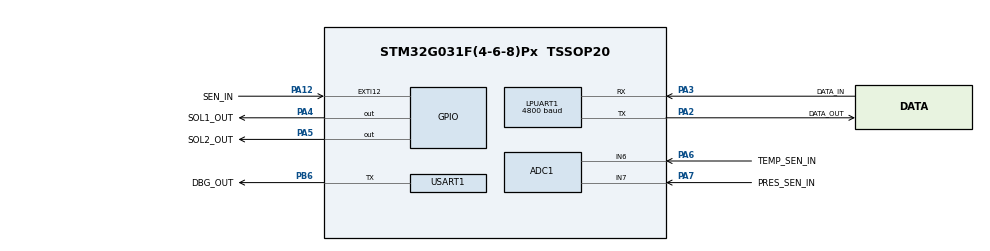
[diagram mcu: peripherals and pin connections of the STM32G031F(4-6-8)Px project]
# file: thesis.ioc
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ADC1.Channel-1\#ChannelRegularConversion=ADC_CHANNEL_7
ADC1.ContinuousConvMode=DISABLE
ADC1.DMAContinuousRequests=ENABLE
ADC1.EOCSelection=ADC_EOC_SINGLE_CONV
ADC1.NbrOfConversion=1
ADC1.NbrOfConversionFlag=1
ADC1.Overrun=ADC_OVR_DATA_OVERWRITTEN
ADC1.Rank-1\#ChannelRegularConversion=1
ADC1.SamplingTime-1\#ChannelRegularConversion=ADC_SAMPLINGTIME_COMMON_1
ADC1.SelectedChannel=ADC_CHANNEL_6|ADC_CHANNEL_7
ADC1.master=1
Dma.ADC1.0.Direction=DMA_PERIPH_TO_MEMORY
Dma.ADC1.0.EventEnable=DISABLE
Dma.ADC1.0.Instance=DMA1_Channel3
Dma.ADC1.0.MemDataAlignment=DMA_MDATAALIGN_HALFWORD
Dma.ADC1.0.MemInc=DMA_MINC_ENABLE
Dma.ADC1.0.Mode=DMA_NORMAL
Dma.ADC1.0.PeriphDataAlignment=DMA_PDATAALIGN_HALFWORD
Dma.ADC1.0.PeriphInc=DMA_PINC_DISABLE
Dma.ADC1.0.Polarity=HAL_DMAMUX_REQ_GEN_RISING
Dma.ADC1.0.Priority=DMA_PRIORITY_LOW
Dma.ADC1.0.RequestNumber=1
Dma.ADC1.0.SignalID=NONE
Dma.ADC1.0.SyncEnable=DISABLE
Dma.ADC1.0.SyncPolarity=HAL_DMAMUX_SYNC_NO_EVENT
Dma.ADC1.0.SyncRequestNumber=1
Dma.ADC1.0.SyncSignalID=NONE
Dma.LPUART1_RX.3.Direction=DMA_PERIPH_TO_MEMORY
Dma.LPUART1_RX.3.EventEnable=DISABLE
Dma.LPUART1_RX.3.Instance=DMA1_Channel2
Dma.LPUART1_RX.3.MemDataAlignment=DMA_MDATAALIGN_BYTE
Dma.LPUART1_RX.3.MemInc=DMA_MINC_ENABLE
Dma.LPUART1_RX.3.Mode=DMA_NORMAL
Dma.LPUART1_RX.3.PeriphDataAlignment=DMA_PDATAALIGN_BYTE
Dma.LPUART1_RX.3.PeriphInc=DMA_PINC_DISABLE
Dma.LPUART1_RX.3.Polarity=HAL_DMAMUX_REQ_GEN_RISING
Dma.LPUART1_RX.3.Priority=DMA_PRIORITY_LOW
Dma.LPUART1_RX.3.RequestNumber=1
Dma.LPUART1_RX.3.SignalID=NONE
Dma.LPUART1_RX.3.SyncEnable=DISABLE
Dma.LPUART1_RX.3.SyncPolarity=HAL_DMAMUX_SYNC_NO_EVENT
Dma.LPUART1_RX.3.SyncRequestNumber=1
Dma.LPUART1_RX.3.SyncSignalID=NONE
Dma.LPUART1_TX.2.Direction=DMA_MEMORY_TO_PERIPH
Dma.LPUART1_TX.2.EventEnable=DISABLE
Dma.LPUART1_TX.2.Instance=DMA1_Channel1
Dma.LPUART1_TX.2.MemDataAlignment=DMA_MDATAALIGN_BYTE
Dma.LPUART1_TX.2.MemInc=DMA_MINC_ENABLE
Dma.LPUART1_TX.2.Mode=DMA_NORMAL
Dma.LPUART1_TX.2.PeriphDataAlignment=DMA_PDATAALIGN_BYTE
Dma.LPUART1_TX.2.PeriphInc=DMA_PINC_DISABLE
Dma.LPUART1_TX.2.Polarity=HAL_DMAMUX_REQ_GEN_RISING
Dma.LPUART1_TX.2.Priority=DMA_PRIORITY_LOW
Dma.LPUART1_TX.2.RequestNumber=1
Dma.LPUART1_TX.2.SignalID=NONE
Dma.LPUART1_TX.2.SyncEnable=DISABLE
Dma.LPUART1_TX.2.SyncPolarity=HAL_DMAMUX_SYNC_NO_EVENT
Dma.LPUART1_TX.2.SyncRequestNumber=1
Dma.LPUART1_TX.2.SyncSignalID=NONE
Dma.Request0=ADC1
Dma.Request1=USART1_TX
Dma.Request2=LPUART1_TX
Dma.Request3=LPUART1_RX
Dma.USART1_TX.1.Direction=DMA_MEMORY_TO_PERIPH
Dma.USART1_TX.1.EventEnable=DISABLE
Dma.USART1_TX.1.Instance=DMA1_Channel4
Dma.USART1_TX.1.MemDataAlignment=DMA_MDATAALIGN_BYTE
Dma.USART1_TX.1.MemInc=DMA_MINC_ENABLE
Dma.USART1_TX.1.Mode=DMA_NORMAL
Dma.USART1_TX.1.PeriphDataAlignment=DMA_PDATAALIGN_BYTE
Dma.USART1_TX.1.PeriphInc=DMA_PINC_DISABLE
Dma.USART1_TX.1.Polarity=HAL_DMAMUX_REQ_GEN_RISING
Dma.USART1_TX.1.Priority=DMA_PRIORITY_LOW
Dma.USART1_TX.1.RequestNumber=1
Dma.USART1_TX.1.SignalID=NONE
Dma.USART1_TX.1.SyncEnable=DISABLE
Dma.USART1_TX.1.SyncPolarity=HAL_DMAMUX_SYNC_NO_EVENT
Dma.USART1_TX.1.SyncRequestNumber=1
Dma.USART1_TX.1.SyncSignalID=NONE
LPTIM1.ClockPrescaler=LPTIM_PRESCALER_DIV32
LPTIM2.ClockPrescaler=LPTIM_PRESCALER_DIV32
LPUART1.BaudRate=4800
LPUART1.WordLength=UART_WORDLENGTH_8B
Mcu.Family=STM32G0
Mcu.Name=STM32G031F(4-6-8)Px
Mcu.Package=TSSOP20
NVIC.ADC1_IRQn=true\:0\:0\:false\:false\:true\:true\:true\:true
NVIC.DMA1_Ch4_5_DMAMUX1_OVR_IRQn=true\:0\:0\:false\:false\:true\:false\:true\:true
NVIC.DMA1_Channel1_IRQn=true\:0\:0\:false\:false\:true\:false\:true\:true
NVIC.DMA1_Channel2_3_IRQn=true\:0\:0\:false\:false\:true\:false\:true\:true
NVIC.EXTI4_15_IRQn=true\:0\:0\:false\:false\:true\:true\:true\:true
NVIC.LPTIM1_IRQn=true\:0\:0\:false\:false\:true\:true\:true\:true
NVIC.LPTIM2_IRQn=true\:0\:0\:false\:false\:true\:true\:true\:true
NVIC.LPUART1_IRQn=true\:0\:0\:false\:false\:true\:true\:true\:true
PA12\ [PA10].GPIO_Label=SEN_IN
PA12\ [PA10].Signal=GPXTI12
PA13.Mode=Serial_Wire
PA13.Signal=SYS_SWDIO
PA14-BOOT0.Mode=Serial_Wire
PA14-BOOT0.Signal=SYS_SWCLK
PA14-BOOT0__PA15.StandardMode=true
PA2.GPIO_Label=DATA_OUT
PA2.Mode=Asynchronous
PA2.Signal=LPUART1_TX
PA3.GPIO_Label=DATA_IN
PA3.Mode=Asynchronous
PA3.Signal=LPUART1_RX
PA4.GPIO_Label=SOL1_OUT
PA4.Signal=GPIO_Output
PA5.GPIO_Label=SOL2_OUT
PA5.Signal=GPIO_Output
PA6.GPIO_Label=TEMP_SEN_IN
PA6.Mode=IN6
PA6.Signal=ADC1_IN6
PA7.GPIO_Label=PRES_SEN_IN
PA7.Mode=IN7
PA7.Signal=ADC1_IN7
PB0__PB1__PB2__PA8.StandardMode=true
PB3__PB4__PB5__PB6.StandardMode=true
PB6.GPIO_Label=DBG_OUT
PB6.Mode=Half_duplex(single_wire_mode)
PB6.Signal=USART1_TX
PB7__PB8.StandardMode=true
PC14-OSC32_IN\ (PC14).Mode=LSE-External-Clock-Source
PC14-OSC32_IN\ (PC14).Signal=RCC_OSC32_IN
PC14-OSC32_IN\ (PC14)__PB9.StandardMode=true
ProjectManager.HeapSize=0x200
ProjectManager.StackSize=0x400
ProjectManager.TargetToolchain=STM32CubeIDE
RCC.ADCFreq_Value=16000000
RCC.AHBFreq_Value=16000000
RCC.CortexFreq_Value=16000000
RCC.EXTERNAL_CLOCK_VALUE=12288000
RCC.HCLKFreq_Value=16000000
RCC.HSE_VALUE=8000000
RCC.HSI_VALUE=16000000
RCC.LPTIM1CLockSelection=RCC_LPTIM1CLKSOURCE_LSE
RCC.LPTIM2CLockSelection=RCC_LPTIM2CLKSOURCE_LSE
RCC.LPUART1CLockSelection=RCC_LPUART1CLKSOURCE_LSE
RCC.PLLQ=RCC_PLLQ_DIV8
RCC.SYSCLKFreq_VALUE=16000000
RCC.USART1CLockSelection=RCC_USART1CLKSOURCE_HSI
RCC.VCOOutputFreq_Value=128000000
USART1.Mode=MODE_TX
USART1.VirtualMode-Half_duplex(single_wire_mode)=VM_ASYNC
VP_LPTIM1_VS_LPTIM_counterModeInternalClock.Mode=Counts__internal_clock_event_00
VP_LPTIM2_VS_LPTIM_counterModeInternalClock.Mode=Counts__internal_clock_event_00
board=custom

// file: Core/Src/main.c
/* USER CODE BEGIN Header */
/**
  ******************************************************************************
  * @file           : main.c
  * @brief          : Main program body
  ******************************************************************************
  * @attention
  *
  * Copyright (c) 2025 STMicroelectronics.
  * All rights reserved.
  *
  * This software is licensed under terms that can be found in the LICENSE file
  * in the root directory of this software component.
  * If no LICENSE file comes with this software, it is provided AS-IS.
  *
  ******************************************************************************
  */
/* USER CODE END Header */
#include "main.h"
#include "adc.h"
#include "dma.h"
#include "lptim.h"
#include "usart.h"
#include "gpio.h"

/* USER CODE BEGIN Includes */
#include "uph_fsm.h"
/* USER CODE END Includes */

void SystemClock_Config(void);

int main(void)
{

  /* MCU Configuration--------------------------------------------------------*/

  /* Reset of all peripherals, Initializes the Flash interface and the Systick. */
  LL_APB2_GRP1_EnableClock(LL_APB2_GRP1_PERIPH_SYSCFG);
  LL_APB1_GRP1_EnableClock(LL_APB1_GRP1_PERIPH_PWR);

  /* SysTick_IRQn interrupt configuration */
  NVIC_SetPriority(SysTick_IRQn, 3);

  /* Configure the system clock */
  SystemClock_Config();

  /* Initialize all configured peripherals */
  MX_GPIO_Init();
  MX_DMA_Init();
  MX_ADC1_Init();
  MX_LPUART1_UART_Init();
  MX_LPTIM1_Init();
  MX_USART1_UART_Init();
  MX_LPTIM2_Init();
  /* USER CODE BEGIN 2 */
  lpuart_dma_receive();
  fsm_set_state(FSM_STATE_IDLE);
  /* USER CODE END 2 */

  /* Infinite loop */
  /* USER CODE BEGIN WHILE */
  while (1)
  {
	fsm_run();
    /* USER CODE END WHILE */

  }
}

void SystemClock_Config(void)
{
  /* HSI configuration and activation */
  LL_RCC_HSI_Enable();
  while(LL_RCC_HSI_IsReady() != 1)
  {
  }

  LL_PWR_EnableBkUpAccess();
  /* LSE configuration and activation */
  LL_RCC_LSE_EnableBypass();
  LL_RCC_LSE_Enable();
  while(LL_RCC_LSE_IsReady() != 1)
  {
  }

  /* Set AHB prescaler*/
  LL_RCC_SetAHBPrescaler(LL_RCC_SYSCLK_DIV_1);

  /* Sysclk activation on the HSI */
  LL_RCC_SetSysClkSource(LL_RCC_SYS_CLKSOURCE_HSI);
  while(LL_RCC_GetSysClkSource() != LL_RCC_SYS_CLKSOURCE_STATUS_HSI)
  {
  }

  /* Set APB1 prescaler*/
  LL_RCC_SetAPB1Prescaler(LL_RCC_APB1_DIV_1);

  LL_Init1msTick(16000000);

  /* Update CMSIS variable (which can be updated also through SystemCoreClockUpdate function) */
  LL_SetSystemCoreClock(16000000);
}

void Error_Handler(void)
{
  __disable_irq();
  while (1)
  {
  }
}
